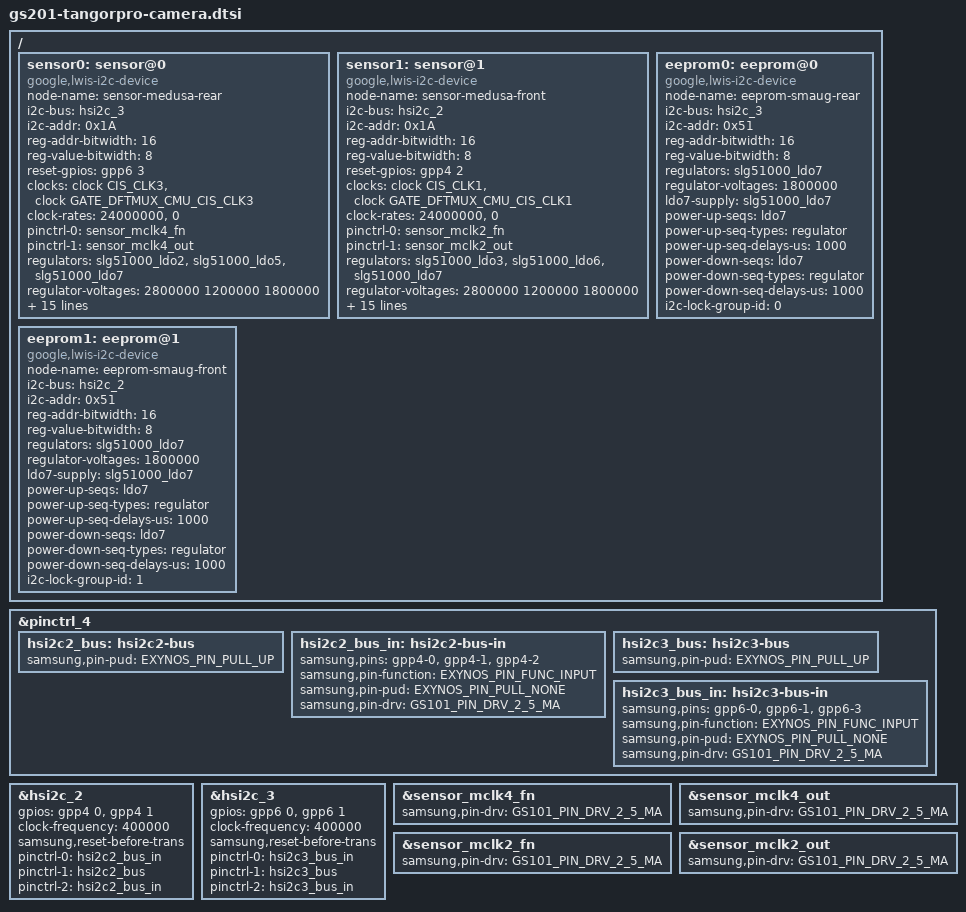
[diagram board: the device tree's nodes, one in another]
// SPDX-License-Identifier: GPL-2.0-only
/*
 * gs201 camera lwis device tree for tangorpro
 *
 * Copyright 2022 Google LLC.
 *
 */

#include <dt-bindings/clock/gs201.h>
#include <dt-bindings/gpio/gpio.h>
#include <arm64/exynos/exynos-pinctrl.h>
#include "gs201/gs101-pinctrl.h"

&pinctrl_4 {
	hsi2c2_bus: hsi2c2-bus {
		samsung,pin-pud = <EXYNOS_PIN_PULL_UP>;
	};

	hsi2c2_bus_in: hsi2c2-bus-in {
		samsung,pins = "gpp4-0", "gpp4-1", "gpp4-2";
		samsung,pin-function = <EXYNOS_PIN_FUNC_INPUT>;
		samsung,pin-pud = <EXYNOS_PIN_PULL_NONE>;
		samsung,pin-drv = <GS101_PIN_DRV_2_5_MA>;
	};

	hsi2c3_bus: hsi2c3-bus {
		samsung,pin-pud = <EXYNOS_PIN_PULL_UP>;
	};

	hsi2c3_bus_in: hsi2c3-bus-in {
		samsung,pins = "gpp6-0", "gpp6-1", "gpp6-3";
		samsung,pin-function = <EXYNOS_PIN_FUNC_INPUT>;
		samsung,pin-pud = <EXYNOS_PIN_PULL_NONE>;
		samsung,pin-drv = <GS101_PIN_DRV_2_5_MA>;
	};
};

&hsi2c_2 {
	#address-cells = <1>;
	#size-cells = <0>;
	gpios = <&gpp4 0 0 &gpp4 1 0>;
	status = "okay";
	clock-frequency = <400000>;
	samsung,reset-before-trans;

	pinctrl-names = "default","on_i2c","off_i2c";
	pinctrl-0 = <&hsi2c2_bus_in>;
	pinctrl-1 = <&hsi2c2_bus>;
	pinctrl-2 = <&hsi2c2_bus_in>;
};

&hsi2c_3 {
	#address-cells = <1>;
	#size-cells = <0>;
	gpios = <&gpp6 0 0 &gpp6 1 0>; /* RCAM_SCL RCAM_SDA */
	status = "okay";
	clock-frequency = <400000>;
	samsung,reset-before-trans;

	pinctrl-names = "default","on_i2c","off_i2c";
	pinctrl-0 = <&hsi2c3_bus_in>;
	pinctrl-1 = <&hsi2c3_bus>;
	pinctrl-2 = <&hsi2c3_bus_in>;
};

&sensor_mclk4_fn {
	samsung,pin-drv = <GS101_PIN_DRV_2_5_MA>;
};

&sensor_mclk4_out {
	samsung,pin-drv = <GS101_PIN_DRV_2_5_MA>;
};

&sensor_mclk2_fn {
	samsung,pin-drv = <GS101_PIN_DRV_2_5_MA>;
};

&sensor_mclk2_out {
	samsung,pin-drv = <GS101_PIN_DRV_2_5_MA>;
};

/ {
	fragment@lwiscamera {
		target-path = "/";
		__overlay__ {
			/* REAR CAMERA IMX355 */
			sensor0: sensor@0 {
				compatible = "google,lwis-i2c-device";

				/* Device node name */
				node-name = "sensor-medusa-rear";

				/* I2C */
				i2c-bus = <&hsi2c_3>;
				i2c-addr = <0x1A>;

				/* Registers */
				reg-addr-bitwidth = <16>;
				reg-value-bitwidth = <8>;

				/* GPIOs */
				reset-gpios = <&gpp6 3 GPIO_ACTIVE_HIGH>;

				clocks =
					<&clock CIS_CLK3>,
					<&clock GATE_DFTMUX_CMU_CIS_CLK3>;
				clock-names =
					"CIS_CLK3",
					"GATE_DFTMUX_CMU_CIS_CLK3";
				clock-rates =
					<24000000>,
					<0>;

				/* MCLK Control */
				pinctrl-names = "mclk_on", "mclk_off";
				pinctrl-0 = <&sensor_mclk4_fn>;
				pinctrl-1 = <&sensor_mclk4_out>;

				/* Power supplies */
				regulators =
					<&slg51000_ldo2 &slg51000_ldo5
					 &slg51000_ldo7>;
				regulator-voltages =
					<2800000 1200000
					 1800000>;
				ldo2-supply = <&slg51000_ldo2>;
				ldo5-supply = <&slg51000_ldo5>;
				ldo7-supply = <&slg51000_ldo7>;

				/* Power up sequence */
				power-up-seqs =
					"ldo2",
					"ldo5",
					"ldo7",
					"mclk_on",
					"reset";
				power-up-seq-types =
					"regulator",
					"regulator",
					"regulator",
					"pinctrl",
					"gpio";
				power-up-seq-delays-us =
					<0
					 0
					 1000
					 1000
					 12000>;

				/* Power down sequence */
				power-down-seqs =
					"reset",
					"mclk_off",
					"ldo7",
					"ldo5",
					"ldo2";
				power-down-seq-types =
					"gpio",
					"pinctrl",
					"regulator",
					"regulator",
					"regulator";
				power-down-seq-delays-us =
					<0
					 1000
					 0
					 0
					 0>;
				transaction-thread-priority = <99>;

				i2c-lock-group-id = <0>;
			};

			/* FRONT CAMERA IMX355 */
			sensor1: sensor@1 {
				compatible = "google,lwis-i2c-device";

				/* Device node name */
				node-name = "sensor-medusa-front";

				/* I2C */
				i2c-bus = <&hsi2c_2>;
				i2c-addr = <0x1A>;

				/* Registers */
				reg-addr-bitwidth = <16>;
				reg-value-bitwidth = <8>;

				/* GPIOs */
				reset-gpios = <&gpp4 2 GPIO_ACTIVE_HIGH>;

				clocks =
					<&clock CIS_CLK1>,
					<&clock GATE_DFTMUX_CMU_CIS_CLK1>;
				clock-names =
					"CIS_CLK1",
					"GATE_DFTMUX_CMU_CIS_CLK1";
				clock-rates =
					<24000000>,
					<0>;

				/* MCLK Control */
				pinctrl-names = "mclk_on", "mclk_off";
				pinctrl-0 = <&sensor_mclk2_fn>;
				pinctrl-1 = <&sensor_mclk2_out>;

				/* Power supplies */
				regulators =
					<&slg51000_ldo3 &slg51000_ldo6
					 &slg51000_ldo7>;
				regulator-voltages =
					<2800000 1200000
					 1800000>;
				ldo3-supply = <&slg51000_ldo3>;
				ldo6-supply = <&slg51000_ldo6>;
				ldo7-supply = <&slg51000_ldo7>;

				/* Power up sequence */
				power-up-seqs =
					"ldo3",
					"ldo6",
					"ldo7",
					"mclk_on",
					"reset";
				power-up-seq-types =
					"regulator",
					"regulator",
					"regulator",
					"pinctrl",
					"gpio";
				power-up-seq-delays-us =
					<0
					 0
					 1000
					 1000
					 12000>;

				/* Power down sequence */
				power-down-seqs =
					"reset",
					"mclk_off",
					"ldo7",
					"ldo6",
					"ldo3";
				power-down-seq-types =
					"gpio",
					"pinctrl",
					"regulator",
					"regulator",
					"regulator";
				power-down-seq-delays-us =
					<0
					 1000
					 0
					 0
					 0>;
				transaction-thread-priority = <99>;

				i2c-lock-group-id = <1>;
			};

			/* Eeprom m24c64s for imx355-rear */
			eeprom0: eeprom@0 {
				compatible = "google,lwis-i2c-device";

				/* Device node name */
				node-name = "eeprom-smaug-rear";

				/* I2C */
				i2c-bus = <&hsi2c_3>;
				i2c-addr = <0x51>;

				/* Registers */
				reg-addr-bitwidth = <16>;
				reg-value-bitwidth = <8>;

				/* Power supplies */
				regulators = <&slg51000_ldo7>;
				regulator-voltages = <1800000>;
				ldo7-supply = <&slg51000_ldo7>;

				/* Power up sequence */
				power-up-seqs =
					"ldo7";
				power-up-seq-types =
					"regulator";
				power-up-seq-delays-us =
					<1000>;

				/* Power down sequence */
				power-down-seqs =
					"ldo7";
				power-down-seq-types =
					"regulator";
				power-down-seq-delays-us =
					<1000>;

				i2c-lock-group-id = <0>;
			};

			/* Eeprom m24c64s for imx355 */
			eeprom1: eeprom@1 {
				compatible = "google,lwis-i2c-device";

				/* Device node name */
				node-name = "eeprom-smaug-front";

				/* I2C */
				i2c-bus = <&hsi2c_2>;
				i2c-addr = <0x51>;

				/* Registers */
				reg-addr-bitwidth = <16>;
				reg-value-bitwidth = <8>;

				/* Power supplies */
				regulators = <&slg51000_ldo7>;
				regulator-voltages = <1800000>;
				ldo7-supply = <&slg51000_ldo7>;

				/* Power up sequence */
				power-up-seqs =
					"ldo7";
				power-up-seq-types =
					"regulator";
				power-up-seq-delays-us =
					<1000>;

				/* Power down sequence */
				power-down-seqs =
					"ldo7";
				power-down-seq-types =
					"regulator";
				power-down-seq-delays-us =
					<1000>;

				i2c-lock-group-id = <1>;
			};
		};
	};
};
